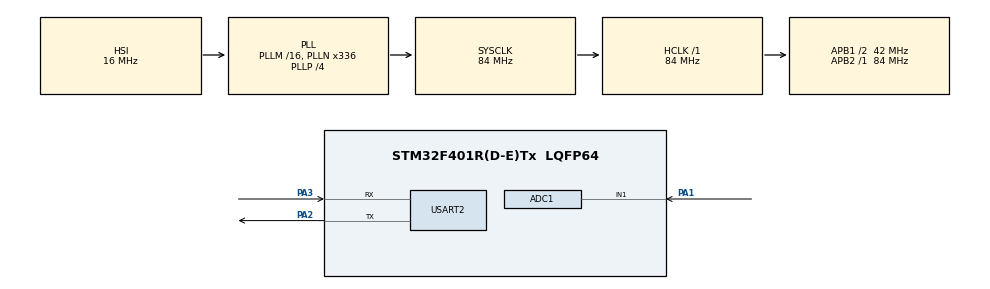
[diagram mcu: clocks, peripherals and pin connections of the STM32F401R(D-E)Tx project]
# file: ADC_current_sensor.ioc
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ADC1.Channel-0\#ChannelRegularConversion=ADC_CHANNEL_1
ADC1.NbrOfConversionFlag=1
ADC1.Rank-0\#ChannelRegularConversion=1
ADC1.SamplingTime-0\#ChannelRegularConversion=ADC_SAMPLETIME_3CYCLES
ADC1.master=1
Mcu.Family=STM32F4
Mcu.Name=STM32F401R(D-E)Tx
Mcu.Package=LQFP64
NVIC.PriorityGroup=NVIC_PRIORITYGROUP_0
PA1.Signal=ADCx_IN1
PA2.Mode=Asynchronous
PA2.Signal=USART2_TX
PA3.Mode=Asynchronous
PA3.Signal=USART2_RX
ProjectManager.HeapSize=0x200
ProjectManager.StackSize=0x400
ProjectManager.TargetToolchain=STM32CubeIDE
RCC.48MHZClocksFreq_Value=48000000
RCC.AHBFreq_Value=84000000
RCC.APB1CLKDivider=RCC_HCLK_DIV2
RCC.APB1Freq_Value=42000000
RCC.APB1TimFreq_Value=84000000
RCC.APB2Freq_Value=84000000
RCC.APB2TimFreq_Value=84000000
RCC.CortexFreq_Value=84000000
RCC.HCLKFreq_Value=84000000
RCC.HSE_VALUE=8000000
RCC.HSI_VALUE=16000000
RCC.LSE_VALUE=32768
RCC.PLLN=336
RCC.PLLP=RCC_PLLP_DIV4
RCC.PLLQ=7
RCC.SYSCLKFreq_VALUE=84000000
RCC.SYSCLKSource=RCC_SYSCLKSOURCE_PLLCLK
RCC.VCOOutputFreq_Value=336000000
SH.ADCx_IN1.0=ADC1_IN1,IN1
USART2.VirtualMode=VM_ASYNC
board=NUCLEO-F401RE

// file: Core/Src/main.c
/* USER CODE BEGIN Header */
/**
  ******************************************************************************
  * @file           : main.c
  * @brief          : Main program body
  ******************************************************************************
  * @attention
  *
  * Copyright (c) 2023 STMicroelectronics.
  * All rights reserved.
  *
  * This software is licensed under terms that can be found in the LICENSE file
  * in the root directory of this software component.
  * If no LICENSE file comes with this software, it is provided AS-IS.
  *
  ******************************************************************************
  */
/* USER CODE END Header */
#include "main.h"
#include "adc.h"
#include "usart.h"
#include "gpio.h"

/* USER CODE BEGIN Includes */
#include <stdio.h>
#include <string.h>
/* USER CODE END Includes */

/* USER CODE BEGIN PD */
#define TRANSMISSION_DELAY (5000)
/* USER CODE END PD */

void SystemClock_Config(void);

/* USER CODE BEGIN 0 */
uint16_t rawValue;
char msg[50];
/* USER CODE END 0 */

int main(void)
{

  /* MCU Configuration--------------------------------------------------------*/

  /* Reset of all peripherals, Initializes the Flash interface and the Systick. */
  HAL_Init();

  /* Configure the system clock */
  SystemClock_Config();

  /* Initialize all configured peripherals */
  MX_GPIO_Init();
  MX_ADC1_Init();
  MX_USART2_UART_Init();
  /* USER CODE BEGIN 2 */
  /* Starts the ADC */
  /* USER CODE END 2 */

  /* Infinite loop */
  /* USER CODE BEGIN WHILE */
  while (1) {
	  HAL_ADC_Start(&hadc1);
	  HAL_ADC_PollForConversion(&hadc1, HAL_MAX_DELAY);

    rawValue = HAL_ADC_GetValue(&hadc1);
    float voltage = ((float)rawValue) / 4095 * 3300;

    sprintf(msg, "\r\n=======================\r\nADC rawValue: %hu\r\n", rawValue);
    HAL_UART_Transmit(&huart2, (uint8_t*) msg, strlen(msg), TRANSMISSION_DELAY);

    sprintf(msg, "Voltage: %.5fmV\r\n", voltage);
    HAL_UART_Transmit(&huart2, (uint8_t*) msg, strlen(msg), TRANSMISSION_DELAY);
    HAL_Delay(1000);
  }
    /* USER CODE END WHILE */

}

void SystemClock_Config(void)
{
  RCC_OscInitTypeDef RCC_OscInitStruct = {0};
  RCC_ClkInitTypeDef RCC_ClkInitStruct = {0};

  /** Configure the main internal regulator output voltage
  */
  __HAL_RCC_PWR_CLK_ENABLE();
  __HAL_PWR_VOLTAGESCALING_CONFIG(PWR_REGULATOR_VOLTAGE_SCALE2);

  /** Initializes the RCC Oscillators according to the specified parameters
  * in the RCC_OscInitTypeDef structure.
  */
  RCC_OscInitStruct.OscillatorType = RCC_OSCILLATORTYPE_HSI;
  RCC_OscInitStruct.HSIState = RCC_HSI_ON;
  RCC_OscInitStruct.HSICalibrationValue = RCC_HSICALIBRATION_DEFAULT;
  RCC_OscInitStruct.PLL.PLLState = RCC_PLL_ON;
  RCC_OscInitStruct.PLL.PLLSource = RCC_PLLSOURCE_HSI;
  RCC_OscInitStruct.PLL.PLLM = 16;
  RCC_OscInitStruct.PLL.PLLN = 336;
  RCC_OscInitStruct.PLL.PLLP = RCC_PLLP_DIV4;
  RCC_OscInitStruct.PLL.PLLQ = 7;
  if (HAL_RCC_OscConfig(&RCC_OscInitStruct) != HAL_OK)
  {
    Error_Handler();
  }

  /** Initializes the CPU, AHB and APB buses clocks
  */
  RCC_ClkInitStruct.ClockType = RCC_CLOCKTYPE_HCLK|RCC_CLOCKTYPE_SYSCLK
                              |RCC_CLOCKTYPE_PCLK1|RCC_CLOCKTYPE_PCLK2;
  RCC_ClkInitStruct.SYSCLKSource = RCC_SYSCLKSOURCE_PLLCLK;
  RCC_ClkInitStruct.AHBCLKDivider = RCC_SYSCLK_DIV1;
  RCC_ClkInitStruct.APB1CLKDivider = RCC_HCLK_DIV2;
  RCC_ClkInitStruct.APB2CLKDivider = RCC_HCLK_DIV1;

  if (HAL_RCC_ClockConfig(&RCC_ClkInitStruct, FLASH_LATENCY_2) != HAL_OK)
  {
    Error_Handler();
  }
}

void Error_Handler(void)
{
  __disable_irq();
  while (1)
  {
  }
}
